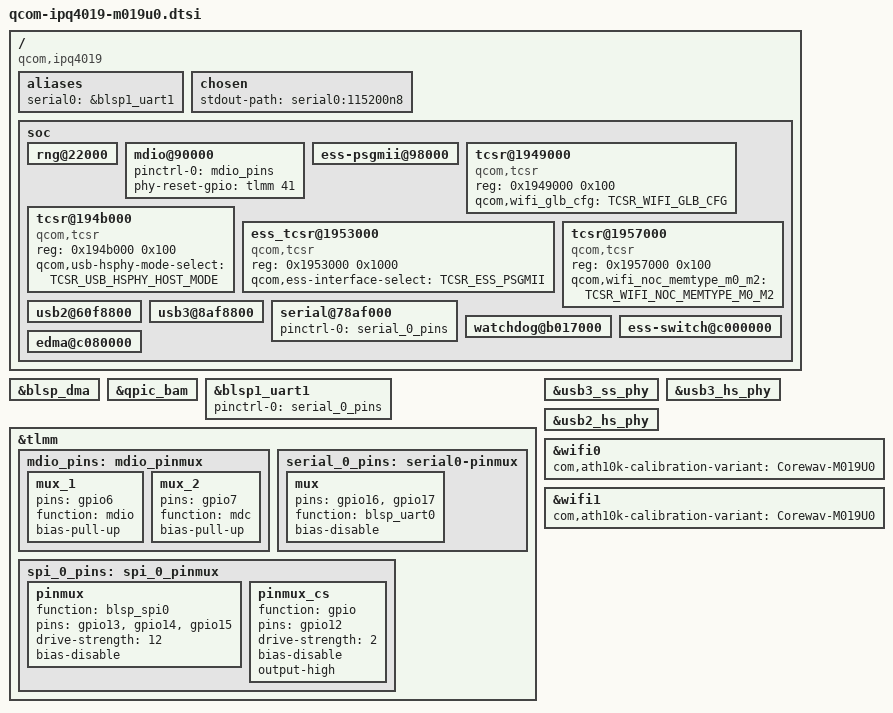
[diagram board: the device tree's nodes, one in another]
// SPDX-License-Identifier: GPL-2.0-or-later OR MIT

#include "qcom-ipq4019.dtsi"
#include <dt-bindings/gpio/gpio.h>
#include <dt-bindings/input/input.h>
#include <dt-bindings/soc/qcom,tcsr.h>

/ {
	compatible = "qcom,ipq4019";

	aliases {
		serial0 = &blsp1_uart1;
	};

	chosen {
		stdout-path = "serial0:115200n8";
	};

	soc {
		rng@22000 {
			status = "okay";
		};

		mdio@90000 {
			status = "okay";
			pinctrl-0 = <&mdio_pins>;
			pinctrl-names = "default";
			phy-reset-gpio = <&tlmm 41 0>;
		};

		ess-psgmii@98000 {
			status = "okay";
		};

		tcsr@1949000 {
			compatible = "qcom,tcsr";
			reg = <0x1949000 0x100>;
			qcom,wifi_glb_cfg = <TCSR_WIFI_GLB_CFG>;
		};

		tcsr@194b000 {
			compatible = "qcom,tcsr";
			reg = <0x194b000 0x100>;
			qcom,usb-hsphy-mode-select = <TCSR_USB_HSPHY_HOST_MODE>;
			status = "okay";
		};

		ess_tcsr@1953000 {
			compatible = "qcom,tcsr";
			reg = <0x1953000 0x1000>;
			qcom,ess-interface-select = <TCSR_ESS_PSGMII>;
		};

		tcsr@1957000 {
			compatible = "qcom,tcsr";
			reg = <0x1957000 0x100>;
			qcom,wifi_noc_memtype_m0_m2 = <TCSR_WIFI_NOC_MEMTYPE_M0_M2>;
		};

		usb2@60f8800 {
			status = "okay";
		};

		usb3@8af8800 {
			status = "okay";
		};

		serial@78af000 {
			pinctrl-0 = <&serial_0_pins>;
			pinctrl-names = "default";
			status = "okay";
		};

		watchdog@b017000 {
			status = "okay";
		};

		ess-switch@c000000 {
			status = "okay";
		};

		edma@c080000 {
			status = "okay";
		};
	};
};

&blsp_dma {
	status = "okay";
};

&qpic_bam {
	status = "okay";
};

&blsp1_uart1 {
	pinctrl-0 = <&serial_0_pins>;
	pinctrl-names = "default";
	status = "okay";
};

&tlmm {
	mdio_pins: mdio_pinmux {
		mux_1 {
			pins = "gpio6";
			function = "mdio";
			bias-pull-up;
		};
		mux_2 {
			pins = "gpio7";
			function = "mdc";
			bias-pull-up;
		};
	};

	serial_0_pins: serial0-pinmux {
		mux {
			pins = "gpio16", "gpio17";
			function = "blsp_uart0";
			bias-disable;
		};
	};

	spi_0_pins: spi_0_pinmux {
		pinmux {
			function = "blsp_spi0";
			pins = "gpio13", "gpio14", "gpio15";
			drive-strength = <12>;
			bias-disable;
		};

		pinmux_cs {
			function = "gpio";
			pins = "gpio12";
			drive-strength = <2>;
			bias-disable;
			output-high;
		};
	};
};

&usb3_ss_phy {
	status = "okay";
};

&usb3_hs_phy {
	status = "okay";
};

&usb2_hs_phy {
	status = "okay";
};

&wifi0 {
	status = "okay";
	com,ath10k-calibration-variant = "Corewav-M019U0";
};

&wifi1 {
	status = "okay";
	com,ath10k-calibration-variant = "Corewav-M019U0";
};

